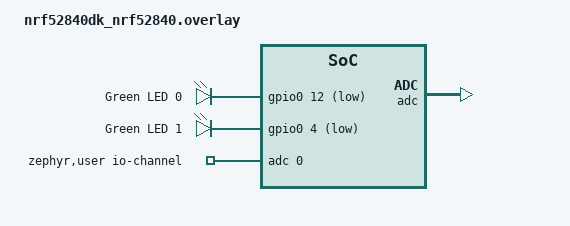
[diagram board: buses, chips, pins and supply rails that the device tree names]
/ {
	leds {
		compatible = "gpio-leds";

		led0: led_0 {
			status = "disabled";
		};

		led1: led_1 {
			gpios = <&gpio0 12 GPIO_ACTIVE_LOW>;
			label = "Green LED 0";
		};

		led2: led_2 {
			gpios = <&gpio0 4 GPIO_ACTIVE_LOW>;
			label = "Green LED 1";
		};

		led3: led_3 {
			status = "disabled";
		};
	};

	/*
	 * Node name must be "zephyr,user" (comma, not underscore).
	 * edtlib only infers the special zephyr,user binding for the exact
	 * path "/zephyr,user", which is what makes the io-channels
	 * phandle-array property generate DT_IO_CHANNELS_* macros.
	 */
	zephyr,user {
		io-channels = <&adc 0>;
	};
};

&gpio0 {
	status = "okay";
};

&adc {
	status = "okay";
};
